VERSION ""

NS_ :

BS_:

BU_: AEM_EMS_4 RIGHT_CAN_CONTROLLER LEFT_CAN_CONTROLLER SIDEPOD_CAN_CONTROLLER

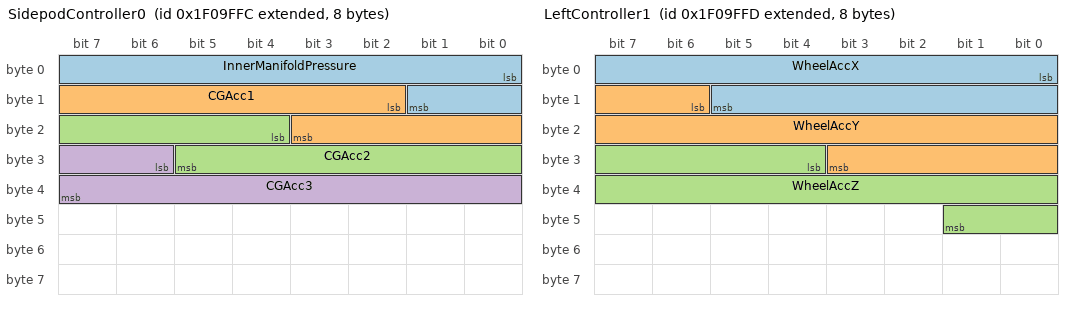
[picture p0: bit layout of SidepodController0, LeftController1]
BO_ 2180030460 SidepodController0: 8 SIDEPOD_CAN_CONTROLLER
 SG_ InnerManifoldPressure : 0|10@1+ (1,0) [0|1023] "pressure:adc" Vector__XXX
 SG_ CGAcc1 : 10|10@1+ (0.012219,-6.215) [-5|5] "acceleration:G" Vector__XXX
 SG_ CGAcc2 : 20|10@1+ (0.012219,-6.215) [-5|5] "acceleration:G" Vector__XXX
 SG_ CGAcc3 : 30|10@1+ (0.012219,-6.215) [-5|5] "acceleration:G" Vector__XXX

BO_ 2180030461 LeftController1: 8 LEFT_CAN_CONTROLLER
 SG_ WheelAccX : 0|14@1- (0.009576,0) [-80|80] "acceleration:m/s^2" Vector__XXX
 SG_ WheelAccY : 14|14@1- (0.009576,0) [-80|80] "acceleration:m/s^2" Vector__XXX
 SG_ WheelAccZ : 28|14@1- (-0.009576,0) [-80|80] "acceleration:m/s^2" Vector__XXX

BO_ 2180030462 LeftController0: 8 LEFT_CAN_CONTROLLER
 SG_ RadiatorTopTemp : 0|10@1+ (-0.6468863,380.4853) [-58|302] "temperature:degF"
 SG_ RadiatorBottomTemp : 10|10@1+ (-0.6468863,380.4853) [-58|302] "temperature:degF" Vector__XXX

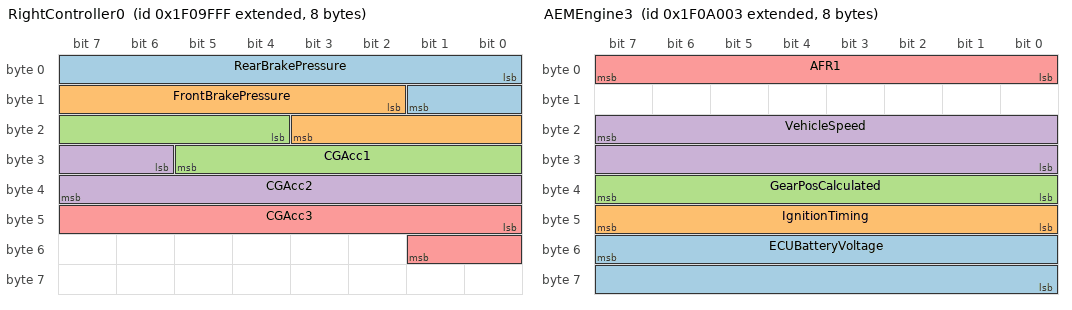
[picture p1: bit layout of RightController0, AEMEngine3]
BO_ 2180030463 RightController0: 8 RIGHT_CAN_CONTROLLER
 SG_ RearBrakePressure : 0|10@1+ (0.97694,0) [0|1000] "pressure:psi"
 SG_ FrontBrakePressure : 10|10@1+ (0.97694,0) [0|1000] "pressure:psi" Vector__XXX
 SG_ CGAcc1 : 20|10@1+ (0.012219,-6.215) [-5|5] "acceleration:G" Vector__XXX
 SG_ CGAcc2 : 30|10@1+ (0.012219,-6.215) [-5|5] "acceleration:G" Vector__XXX
 SG_ CGAcc3 : 40|10@1+ (0.012219,-6.215) [-5|5] "acceleration:G" Vector__XXX

BO_ 2180030467 AEMEngine3: 8 AEM_EMS_4
 SG_ ECUBatteryVoltage : 55|16@0+ (0.0002455,0) [0|16.089] "voltage:V" Vector__XXX
 SG_ IgnitionTiming : 47|8@0+ (0.35156,-17) [-17|72.65] "angle:deg" Vector__XXX
 SG_ GearPosCalculated : 39|8@0+ (1,0) [0|255] "unitless:" Vector__XXX
 SG_ VehicleSpeed : 23|16@0+ (0.00390625,0) [0|255.99609375] "speed:mph" Vector__XXX
 SG_ AFR1 : 7|8@0+ (0.057227,7.325) [7.325|21.917885] "afr:AFR Gasoline" Vector__XXX

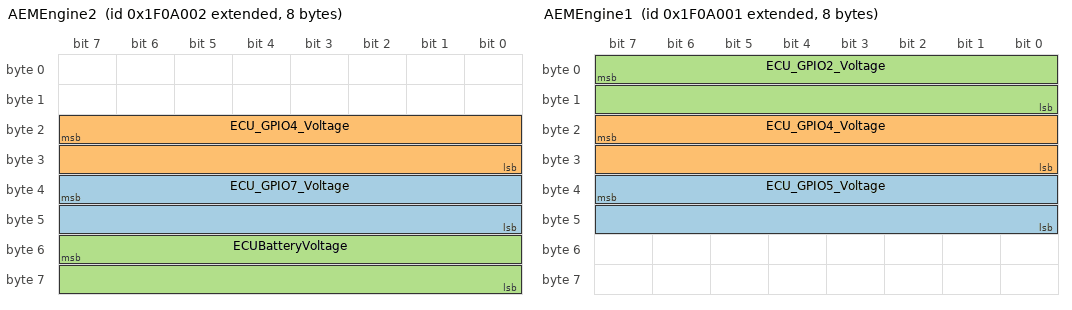
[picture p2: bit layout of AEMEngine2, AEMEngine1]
BO_ 2180030466 AEMEngine2: 8 AEM_EMS_4
 SG_ ECU_GPIO7_Voltage : 39|16@0+ (7.782E-005,0) [0|5.0999] "voltage:V" Vector__XXX
 SG_ ECU_GPIO4_Voltage : 23|16@0+ (7.782E-005,0) [0|5.0999] "voltage:V" Vector__XXX
 SG_ ECUBatteryVoltage : 55|16@0+ (0.000326,0) [0|21.36441] "voltage:V" Vector__XXX

BO_ 2180030465 AEMEngine1: 8 AEM_EMS_4
 SG_ ECU_GPIO5_Voltage : 39|16@0+ (7.782E-005,0) [0|5.0999] "voltage:V" Vector__XXX
 SG_ ECU_GPIO4_Voltage : 23|16@0+ (7.782E-005,0) [0|5.0999] "voltage:V" Vector__XXX
 SG_ ECU_GPIO2_Voltage : 7|16@0+ (7.782E-005,0) [0|5.0999] "voltage:V" Vector__XXX

BO_ 2180030464 AEMEngine0: 8 AEM_EMS_4
 SG_ CoolantTemp : 63|8@0- (1.8,32) [-198.4|260.6] "temperature:F" Vector__XXX
 SG_ IntakeManifoldAirTemp : 55|8@0- (1.8,32) [-198.4|260.6] "temperature:F" Vector__XXX
 SG_ ThrottlePos : 39|16@0+ (0.0015259,0) [0|99.9998565] "fraction:%" Vector__XXX
 SG_ EngineLoad : 23|16@0+ (0.0015259,0) [0|0] "fraction:%" Vector__XXX
 SG_ MAP : 23|16@0+ (0.0015461,0) [0|0] "pressure:kPa" Vector__XXX
 SG_ EngineSpeed : 7|16@0+ (0.39063,0) [0|25599.94] "angular_speed:rpm" Vector__XXX

BA_DEF_ BO_  "GenMsgSendType" STRING ;
BA_DEF_  "ProtocolType" STRING ;
BA_DEF_  "NmType" STRING ;
BA_DEF_ BO_  "GenMsgCycleTime" INT 1 10000;
BA_DEF_ BO_  "GenMsgILSupport" ENUM  "No","Yes";
BA_DEF_ BU_  "ILUsed" ENUM  "No","Yes";
BA_DEF_  "VersionNumber" INT 0 10000;
BA_DEF_  "VersionDay" INT 1 31;
BA_DEF_  "VersionMonth" INT 1 12;
BA_DEF_  "VersionYear" INT 2016 3000;
BA_DEF_  "BusType" STRING ;
BA_DEF_ BO_  "DBC_Author_Contact" STRING ;
BA_DEF_DEF_  "DBC_Author_Contact" "CANbusInfo@AEMelectronics.com";
BA_DEF_DEF_  "GenMsgSendType" "Cyclic";
BA_DEF_DEF_  "ProtocolType" "";
BA_DEF_DEF_  "NmType" "";
BA_DEF_DEF_  "GenMsgCycleTime" 20;
BA_DEF_DEF_  "GenMsgILSupport" "Yes";
BA_DEF_DEF_  "ILUsed" "Yes";
BA_DEF_DEF_  "VersionNumber" 0;
BA_DEF_DEF_  "VersionDay" 1;
BA_DEF_DEF_  "VersionMonth" 1;
BA_DEF_DEF_  "VersionYear" 2016;
BA_DEF_DEF_  "BusType" "Can";
BA_ "ProtocolType" "AEM Net";
BA_ "NmType" "AEM Net";
BA_ "VersionNumber" 3;
BA_ "VersionDay" 28;
BA_ "VersionMonth" 11;
BA_ "BusType" "CAN";
BA_ "GenMsgCycleTime" BO_ 2180030466 16;
BA_ "GenMsgCycleTime" BO_ 2180030465 16;
BA_ "GenMsgCycleTime" BO_ 2180030464 16;
